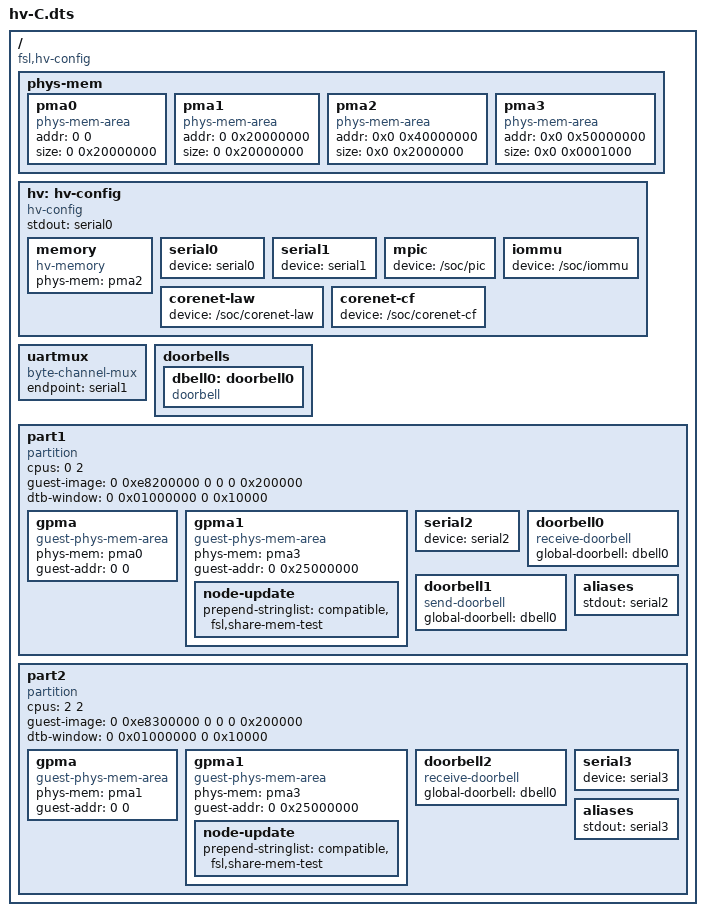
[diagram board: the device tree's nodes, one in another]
/*
 * Copyright (C) 2008,2009 Freescale Semiconductor, Inc.
 *
 * Redistribution and use in source and binary forms, with or without
 * modification, are permitted provided that the following conditions
 * are met:
 * 1. Redistributions of source code must retain the above copyright
 *    notice, this list of conditions and the following disclaimer.
 * 2. Redistributions in binary form must reproduce the above copyright
 *    notice, this list of conditions and the following disclaimer in the
 *    documentation and/or other materials provided with the distribution.
 *
 * THIS SOFTWARE IS PROVIDED BY THE AUTHOR "AS IS" AND ANY EXPRESS OR
 * IMPLIED WARRANTIES, INCLUDING, BUT NOT LIMITED TO, THE IMPLIED WARRANTIES
 * OF MERCHANTABILITY AND FITNESS FOR A PARTICULAR PURPOSE ARE DISCLAIMED.  IN
 * NO EVENT SHALL THE AUTHOR BE LIABLE FOR ANY DIRECT, INDIRECT, INCIDENTAL,
 * SPECIAL, EXEMPLARY, OR CONSEQUENTIAL DAMAGES (INCLUDING, BUT NOT LIMITED
 * TO, PROCUREMENT OF SUBSTITUTE GOODS OR SERVICES; LOSS OF USE, DATA, OR
 * PROFITS; OR BUSINESS INTERRUPTION) HOWEVER CAUSED AND ON ANY THEORY OF
 * LIABILITY, WHETHER IN CONTRACT, STRICT LIABILITY, OR TORT (INCLUDING
 * NEGLIGENCE OR OTHERWISE) ARISING IN ANY WAY OUT OF THE USE OF THIS
 * SOFTWARE, EVEN IF ADVISED OF THE POSSIBILITY OF SUCH DAMAGE.
 */

/dts-v1/;

/ {
	compatible = "fsl,hv-config";

	// =====================================================
	// Physical Memory Areas
	// =====================================================
	phys-mem {
		pma0: pma0 {
			compatible = "phys-mem-area";
			addr = <0 0>;
			size = <0 0x20000000>;
		};

		pma1: pma1 {
			compatible = "phys-mem-area";
			addr = <0 0x20000000>;
			size = <0 0x20000000>;
		};

		pma2: pma2 {
			compatible = "phys-mem-area";
			addr = <0x0 0x40000000>;
			size = <0x0 0x2000000>;
		};

		pma3: pma3 {
			compatible = "phys-mem-area";
			addr = <0x0 0x50000000>;
			size = <0x0 0x0001000>;
		};

	};

	// =====================================================
	// Hypervisor Config
	// =====================================================
	hv: hv-config {
		compatible = "hv-config";
		stdout = <&serial0>;

		memory {
			compatible = "hv-memory";
			phys-mem = <&pma2>;
		};

		serial0: serial0 {
			// Hypervisor console
			device = "serial0";
		};

		serial1: serial1 {
			// Byte channel
			device = "serial1";
		};

		mpic {
			device = "/soc/pic";
		};

		iommu {
			device = "/soc/iommu";
		};

		corenet-law {
			device = "/soc/corenet-law";
		};

		corenet-cf {
			device = "/soc/corenet-cf";
		};
	};

	uartmux: uartmux {
		compatible = "byte-channel-mux";
		endpoint = <&serial1>;
	};

	doorbells {
		dbell0: doorbell0 {
			compatible = "doorbell";
		};
	};

	// =====================================================
	// Partition 1
	// =====================================================
	part1 {
		compatible = "partition";
		cpus = <0 2>;
		guest-image = <0 0xe8200000 0 0 0 0x200000>;
		dtb-window = <0 0x01000000 0 0x10000>;

		gpma {
			compatible = "guest-phys-mem-area";
			phys-mem = <&pma0>;
			guest-addr = <0 0>;
		};

		gpma1 {
			compatible = "guest-phys-mem-area";
			phys-mem = <&pma3>;
			guest-addr = <0 0x25000000>;
			node-update {
				prepend-stringlist = "compatible", "fsl,share-mem-test";
			};
		};

		serial2: serial2 {
			device = "serial2";
		};

		doorbell0 {
			compatible = "receive-doorbell";
			global-doorbell = <&dbell0>;
		};

		doorbell1 {
			compatible = "send-doorbell";
			global-doorbell = <&dbell0>;
		};

		aliases {
			stdout = <&serial2>;
		};
	};

	// =====================================================
	// Partition 2
	// =====================================================
	part2 {
		compatible = "partition";
		cpus = <2 2>;
		guest-image = <0 0xe8300000 0 0 0 0x200000>;
		dtb-window = <0 0x01000000 0 0x10000>;

		gpma {
			compatible = "guest-phys-mem-area";
			phys-mem = <&pma1>;
			guest-addr = <0 0>;
		};

		gpma1 {
			compatible = "guest-phys-mem-area";
			phys-mem = <&pma3>;
			guest-addr = <0 0x25000000>;
			node-update {
				prepend-stringlist = "compatible", "fsl,share-mem-test";
			};
		};

		doorbell2 {
			compatible = "receive-doorbell";
			global-doorbell = <&dbell0>;
		};

		serial3: serial3 {
			device = "serial3";
		};

		aliases {
			stdout = <&serial3>;
		};
	};
};
